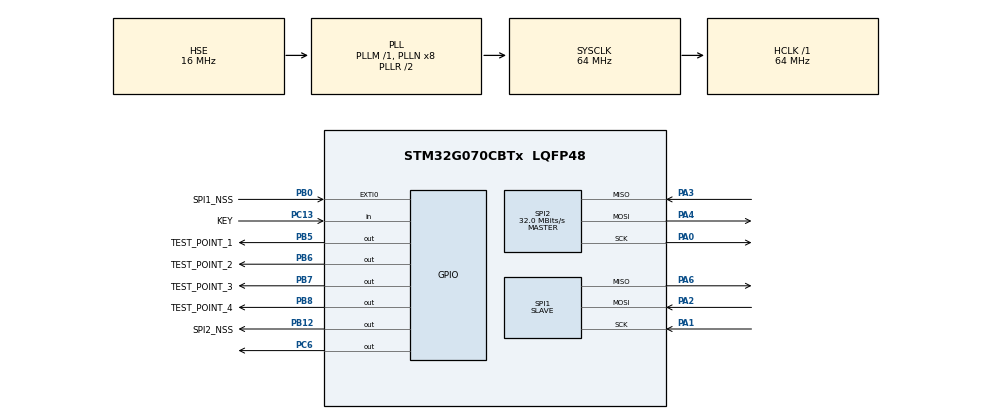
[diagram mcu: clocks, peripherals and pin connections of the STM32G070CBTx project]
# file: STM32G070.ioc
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Dma.Request0=SPI2_RX
Dma.Request1=SPI2_TX
Dma.Request2=SPI1_RX
Dma.Request3=SPI1_TX
Dma.SPI1_RX.2.Direction=DMA_PERIPH_TO_MEMORY
Dma.SPI1_RX.2.EventEnable=DISABLE
Dma.SPI1_RX.2.Instance=DMA1_Channel3
Dma.SPI1_RX.2.MemDataAlignment=DMA_MDATAALIGN_HALFWORD
Dma.SPI1_RX.2.MemInc=DMA_MINC_ENABLE
Dma.SPI1_RX.2.Mode=DMA_NORMAL
Dma.SPI1_RX.2.PeriphDataAlignment=DMA_PDATAALIGN_HALFWORD
Dma.SPI1_RX.2.PeriphInc=DMA_PINC_DISABLE
Dma.SPI1_RX.2.Polarity=HAL_DMAMUX_REQ_GEN_RISING
Dma.SPI1_RX.2.Priority=DMA_PRIORITY_VERY_HIGH
Dma.SPI1_RX.2.RequestNumber=1
Dma.SPI1_RX.2.SignalID=NONE
Dma.SPI1_RX.2.SyncEnable=DISABLE
Dma.SPI1_RX.2.SyncPolarity=HAL_DMAMUX_SYNC_NO_EVENT
Dma.SPI1_RX.2.SyncRequestNumber=1
Dma.SPI1_RX.2.SyncSignalID=NONE
Dma.SPI1_TX.3.Direction=DMA_MEMORY_TO_PERIPH
Dma.SPI1_TX.3.EventEnable=DISABLE
Dma.SPI1_TX.3.Instance=DMA1_Channel4
Dma.SPI1_TX.3.MemDataAlignment=DMA_MDATAALIGN_HALFWORD
Dma.SPI1_TX.3.MemInc=DMA_MINC_ENABLE
Dma.SPI1_TX.3.Mode=DMA_NORMAL
Dma.SPI1_TX.3.PeriphDataAlignment=DMA_PDATAALIGN_HALFWORD
Dma.SPI1_TX.3.PeriphInc=DMA_PINC_DISABLE
Dma.SPI1_TX.3.Polarity=HAL_DMAMUX_REQ_GEN_RISING
Dma.SPI1_TX.3.Priority=DMA_PRIORITY_LOW
Dma.SPI1_TX.3.RequestNumber=1
Dma.SPI1_TX.3.SignalID=NONE
Dma.SPI1_TX.3.SyncEnable=DISABLE
Dma.SPI1_TX.3.SyncPolarity=HAL_DMAMUX_SYNC_NO_EVENT
Dma.SPI1_TX.3.SyncRequestNumber=1
Dma.SPI1_TX.3.SyncSignalID=NONE
Dma.SPI2_RX.0.Direction=DMA_PERIPH_TO_MEMORY
Dma.SPI2_RX.0.EventEnable=DISABLE
Dma.SPI2_RX.0.Instance=DMA1_Channel1
Dma.SPI2_RX.0.MemDataAlignment=DMA_MDATAALIGN_HALFWORD
Dma.SPI2_RX.0.MemInc=DMA_MINC_ENABLE
Dma.SPI2_RX.0.Mode=DMA_NORMAL
Dma.SPI2_RX.0.PeriphDataAlignment=DMA_PDATAALIGN_HALFWORD
Dma.SPI2_RX.0.PeriphInc=DMA_PINC_DISABLE
Dma.SPI2_RX.0.Polarity=HAL_DMAMUX_REQ_GEN_RISING
Dma.SPI2_RX.0.Priority=DMA_PRIORITY_HIGH
Dma.SPI2_RX.0.RequestNumber=1
Dma.SPI2_RX.0.SignalID=NONE
Dma.SPI2_RX.0.SyncEnable=ENABLE
Dma.SPI2_RX.0.SyncPolarity=HAL_DMAMUX_SYNC_RISING
Dma.SPI2_RX.0.SyncRequestNumber=1
Dma.SPI2_RX.0.SyncSignalID=NONE
Dma.SPI2_TX.1.Direction=DMA_MEMORY_TO_PERIPH
Dma.SPI2_TX.1.EventEnable=DISABLE
Dma.SPI2_TX.1.Instance=DMA1_Channel2
Dma.SPI2_TX.1.MemDataAlignment=DMA_MDATAALIGN_HALFWORD
Dma.SPI2_TX.1.MemInc=DMA_MINC_ENABLE
Dma.SPI2_TX.1.Mode=DMA_NORMAL
Dma.SPI2_TX.1.PeriphDataAlignment=DMA_PDATAALIGN_HALFWORD
Dma.SPI2_TX.1.PeriphInc=DMA_PINC_DISABLE
Dma.SPI2_TX.1.Polarity=HAL_DMAMUX_REQ_GEN_RISING
Dma.SPI2_TX.1.Priority=DMA_PRIORITY_LOW
Dma.SPI2_TX.1.RequestNumber=1
Dma.SPI2_TX.1.SignalID=NONE
Dma.SPI2_TX.1.SyncEnable=DISABLE
Dma.SPI2_TX.1.SyncPolarity=HAL_DMAMUX_SYNC_NO_EVENT
Dma.SPI2_TX.1.SyncRequestNumber=1
Dma.SPI2_TX.1.SyncSignalID=NONE
Mcu.Family=STM32G0
Mcu.Name=STM32G070CBTx
Mcu.Package=LQFP48
NVIC.DMA1_Ch4_7_DMAMUX1_OVR_IRQn=true\:0\:0\:false\:false\:true\:false\:true\:true
NVIC.DMA1_Channel1_IRQn=true\:0\:0\:false\:false\:true\:false\:true\:true
NVIC.DMA1_Channel2_3_IRQn=true\:0\:0\:false\:false\:true\:false\:true\:true
NVIC.EXTI0_1_IRQn=true\:0\:0\:false\:false\:true\:true\:true\:true
NVIC.SPI1_IRQn=true\:0\:0\:false\:false\:true\:true\:true\:true
NVIC.SPI2_IRQn=true\:0\:0\:false\:false\:true\:true\:true\:true
PA0.GPIO_Speed=GPIO_SPEED_FREQ_VERY_HIGH
PA0.Mode=Full_Duplex_Master
PA0.Signal=SPI2_SCK
PA1.GPIO_Speed=GPIO_SPEED_FREQ_VERY_HIGH
PA1.Mode=Full_Duplex_Slave
PA1.Signal=SPI1_SCK
PA13.Mode=Serial_Wire
PA13.Signal=SYS_SWDIO
PA14-BOOT0.Mode=Serial_Wire
PA14-BOOT0.Signal=SYS_SWCLK
PA2.GPIO_Speed=GPIO_SPEED_FREQ_VERY_HIGH
PA2.Mode=Full_Duplex_Slave
PA2.Signal=SPI1_MOSI
PA3.GPIO_Speed=GPIO_SPEED_FREQ_VERY_HIGH
PA3.Mode=Full_Duplex_Master
PA3.Signal=SPI2_MISO
PA4.GPIO_Speed=GPIO_SPEED_FREQ_VERY_HIGH
PA4.Mode=Full_Duplex_Master
PA4.Signal=SPI2_MOSI
PA6.GPIO_Speed=GPIO_SPEED_FREQ_VERY_HIGH
PA6.Mode=Full_Duplex_Slave
PA6.Signal=SPI1_MISO
PB0.GPIO_Label=SPI1_NSS
PB0.GPIO_ModeDefaultEXTI=GPIO_MODE_IT_RISING_FALLING
PB0.Signal=GPXTI0
PB12.GPIO_Label=SPI2_NSS
PB12.GPIO_Speed=GPIO_SPEED_FREQ_VERY_HIGH
PB12.PinState=GPIO_PIN_SET
PB12.Signal=GPIO_Output
PB5.GPIO_Label=TEST_POINT_1
PB5.GPIO_Speed=GPIO_SPEED_FREQ_VERY_HIGH
PB5.Signal=GPIO_Output
PB6.GPIO_FM6=SYSCFG_FASTMODEPLUS_PB6
PB6.GPIO_Label=TEST_POINT_2
PB6.GPIO_Speed=GPIO_SPEED_FREQ_VERY_HIGH
PB6.Signal=GPIO_Output
PB7.GPIO_FM7=SYSCFG_FASTMODEPLUS_PB7
PB7.GPIO_Label=TEST_POINT_3
PB7.GPIO_Speed=GPIO_SPEED_FREQ_VERY_HIGH
PB7.Signal=GPIO_Output
PB8.GPIO_FM8=SYSCFG_FASTMODEPLUS_PB8
PB8.GPIO_Label=TEST_POINT_4
PB8.GPIO_Speed=GPIO_SPEED_FREQ_VERY_HIGH
PB8.Signal=GPIO_Output
PC13.GPIO_Label=KEY
PC13.GPIO_PuPd=GPIO_PULLUP
PC13.Signal=GPIO_Input
PC6.GPIO_Speed=GPIO_SPEED_FREQ_VERY_HIGH
PC6.Signal=GPIO_Output
PF0-OSC_IN\ (PF0).Mode=HSE-External-Oscillator
PF0-OSC_IN\ (PF0).Signal=RCC_OSC_IN
PF1-OSC_OUT\ (PF1).Mode=HSE-External-Oscillator
PF1-OSC_OUT\ (PF1).Signal=RCC_OSC_OUT
ProjectManager.HeapSize=0x200
ProjectManager.StackSize=0x400
ProjectManager.TargetToolchain=EWARM V8.50
RCC.ADCFreq_Value=64000000
RCC.AHBFreq_Value=64000000
RCC.CortexFreq_Value=64000000
RCC.EXTERNAL_CLOCK_VALUE=48000
RCC.HCLKFreq_Value=64000000
RCC.HSE_VALUE=16000000
RCC.HSI_VALUE=16000000
RCC.LSE_VALUE=32768
RCC.PLLSourceVirtual=RCC_PLLSOURCE_HSE
RCC.RCC_MCODiv=RCC_MCODIV_2
RCC.SYSCLKFreq_VALUE=64000000
RCC.SYSCLKSource=RCC_SYSCLKSOURCE_PLLCLK
RCC.VCOOutputFreq_Value=128000000
SPI1.DataSize=SPI_DATASIZE_16BIT
SPI1.Direction=SPI_DIRECTION_2LINES
SPI1.Mode=SPI_MODE_SLAVE
SPI1.VirtualType=VM_SLAVE
SPI2.BaudRatePrescaler=SPI_BAUDRATEPRESCALER_2
SPI2.CalculateBaudRate=32.0 MBits/s
SPI2.DataSize=SPI_DATASIZE_16BIT
SPI2.Direction=SPI_DIRECTION_2LINES
SPI2.Mode=SPI_MODE_MASTER
SPI2.VirtualType=VM_MASTER
board=custom

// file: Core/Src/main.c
/* USER CODE BEGIN Header */
/**
  ******************************************************************************
  * @file           : main.c
  * @brief          : Main program body
  ******************************************************************************
  * @attention
  *
  * Copyright (c) 2022 STMicroelectronics.
  * All rights reserved.
  *
  * This software is licensed under terms that can be found in the LICENSE file
  * in the root directory of this software component.
  * If no LICENSE file comes with this software, it is provided AS-IS.
  *
  ******************************************************************************
  */
/* USER CODE END Header */
#include "main.h"

/* USER CODE BEGIN Includes */
#include "stm32g070xx.h"
/* USER CODE END Includes */

/* USER CODE BEGIN PD */
#define MASTER_TX_RX_BUF_LEN    1024
#define SLAVE_TX_RX_BUF_LEN     MASTER_TX_RX_BUF_LEN

/*#define SPI2_NSS_H2L()          HAL_GPIO_WritePin(SPI2_NSS_GPIO_Port, SPI2_NSS_Pin, GPIO_PIN_RESET)
#define SPI2_NSS_L2H()          HAL_GPIO_WritePin(SPI2_NSS_GPIO_Port, SPI2_NSS_Pin, GPIO_PIN_SET)*/
#define SPI2_NSS_H2L()          SPI2_NSS_GPIO_Port->BRR = (uint32_t)SPI2_NSS_Pin
#define SPI2_NSS_L2H()          SPI2_NSS_GPIO_Port->BSRR = (uint32_t)SPI2_NSS_Pin
/* USER CODE END PD */

SPI_HandleTypeDef hspi1;
SPI_HandleTypeDef hspi2;
DMA_HandleTypeDef hdma_spi1_rx;
DMA_HandleTypeDef hdma_spi1_tx;
DMA_HandleTypeDef hdma_spi2_rx;
DMA_HandleTypeDef hdma_spi2_tx;

/* USER CODE BEGIN PV */
uint16_t        masterTxBuf[MASTER_TX_RX_BUF_LEN];
uint16_t        masterRxBuf[MASTER_TX_RX_BUF_LEN];
uint16_t        slaveTxBuf[SLAVE_TX_RX_BUF_LEN];
uint16_t        slaveRxBuf[SLAVE_TX_RX_BUF_LEN];
uint32_t        time;
/* USER CODE END PV */

void SystemClock_Config(void);
static void MX_GPIO_Init(void);
static void MX_DMA_Init(void);
static void MX_SPI1_Init(void);
static void MX_SPI2_Init(void);
/* USER CODE BEGIN PFP */
void protocol(uint16_t *buf, uint32_t len);
/* USER CODE END PFP */

/* USER CODE BEGIN 0 */

/**
  * @brief  exchange protocol implementation
  * @param[in]  data buffer
  * @param[in]  data length
  * @retval None
  */
void protocol(uint16_t *buf, uint32_t len)
{
        // we get here only if we get a full-size buffer
}

/**
  * @brief  Tx and Rx Transfer completed callback.
  * @param  hspi pointer to a SPI_HandleTypeDef structure that contains the configuration information for SPI module.
  * @retval None
  */
void HAL_SPI_TxRxCpltCallback(SPI_HandleTypeDef *hspi)
{
        if(hspi->Instance == SPI1)
        {
                protocol(slaveRxBuf, SLAVE_TX_RX_BUF_LEN);
        }
}

/**
  * @brief  EXTI line detection callback.
  * @param  GPIO_Pin Specifies the port pin connected to corresponding EXTI line.
  * @retval None
  */
void HAL_GPIO_EXTI_Falling_Callback(uint16_t GPIO_Pin)
{
        HAL_SPI_TransmitReceive_DMA(&hspi1, (uint8_t *)&slaveTxBuf, (uint8_t *)&slaveRxBuf, SLAVE_TX_RX_BUF_LEN);
        GPIOC->BRR =  0xffffffff; // устанавливаем 0 на всем порте
}

/**
  * @brief  EXTI line detection callback.
  * @param  GPIO_Pin Specifies the port pin connected to corresponding EXTI line.
  * @retval None
  */
void HAL_GPIO_EXTI_Rising_Callback(uint16_t GPIO_Pin)
{
        if(hdma_spi1_rx.Instance->CNDTR)
        {
                uint32_t Len = SLAVE_TX_RX_BUF_LEN - hdma_spi1_rx.Instance->CNDTR; // количество полученых слов
                HAL_SPI_DMAStop(&hspi1);
        }
}
/* USER CODE END 0 */

int main(void)
{

  /* MCU Configuration--------------------------------------------------------*/

  /* Reset of all peripherals, Initializes the Flash interface and the Systick. */
  HAL_Init();

  /* Configure the system clock */
  SystemClock_Config();

  /* Initialize all configured peripherals */
  MX_GPIO_Init();
  MX_DMA_Init();
  MX_SPI1_Init();
  MX_SPI2_Init();
  /* USER CODE BEGIN 2 */
        for(uint16_t i = 0;  i < MASTER_TX_RX_BUF_LEN; i++) // generate a set of data for easy tracking of changes in debug mode
                masterTxBuf[i] = MASTER_TX_RX_BUF_LEN - i - 1;
        for(uint16_t i = 0;  i < SLAVE_TX_RX_BUF_LEN; i++) // generate a set of data for easy tracking of changes in debug mode
                slaveTxBuf[i]  = SLAVE_TX_RX_BUF_LEN - i - 1;
  /* USER CODE END 2 */

  /* Infinite loop */
  /* USER CODE BEGIN WHILE */
  while(1)
  {
          time = HAL_GetTick();
          GPIOC->BSRR = 0xffffffff; // устанавливаем 1 на всем порте
          SPI2_NSS_H2L();
          //HAL_Delay(1);
          //HAL_SPI_TransmitReceive(&hspi2, (uint8_t *)&masterTxBuf, (uint8_t *)&masterRxBuf, MASTER_TX_BUF_LEN, 2000);
          HAL_SPI_TransmitReceive_DMA(&hspi2, (uint8_t *)&masterTxBuf, (uint8_t *)&masterRxBuf, MASTER_TX_RX_BUF_LEN);
          while(hdma_spi2_tx.Instance->CNDTR); // wait for the end of the data transfer
          SPI2_NSS_L2H();
          time = HAL_GetTick() - time;
          uint8_t c = 0;
    /* USER CODE END WHILE */

    /* USER CODE BEGIN 3 */
          //HAL_SPI_DMAStop(&hspi1);
  }
  /* USER CODE END 3 */
}

void SystemClock_Config(void)
{
  RCC_OscInitTypeDef RCC_OscInitStruct = {0};
  RCC_ClkInitTypeDef RCC_ClkInitStruct = {0};

  /** Configure the main internal regulator output voltage
  */
  HAL_PWREx_ControlVoltageScaling(PWR_REGULATOR_VOLTAGE_SCALE1);

  /** Initializes the RCC Oscillators according to the specified parameters
  * in the RCC_OscInitTypeDef structure.
  */
  RCC_OscInitStruct.OscillatorType = RCC_OSCILLATORTYPE_HSE;
  RCC_OscInitStruct.HSEState = RCC_HSE_ON;
  RCC_OscInitStruct.PLL.PLLState = RCC_PLL_ON;
  RCC_OscInitStruct.PLL.PLLSource = RCC_PLLSOURCE_HSE;
  RCC_OscInitStruct.PLL.PLLM = RCC_PLLM_DIV1;
  RCC_OscInitStruct.PLL.PLLN = 8;
  RCC_OscInitStruct.PLL.PLLP = RCC_PLLP_DIV2;
  RCC_OscInitStruct.PLL.PLLR = RCC_PLLR_DIV2;
  if (HAL_RCC_OscConfig(&RCC_OscInitStruct) != HAL_OK)
  {
    Error_Handler();
  }

  /** Initializes the CPU, AHB and APB buses clocks
  */
  RCC_ClkInitStruct.ClockType = RCC_CLOCKTYPE_HCLK|RCC_CLOCKTYPE_SYSCLK
                              |RCC_CLOCKTYPE_PCLK1;
  RCC_ClkInitStruct.SYSCLKSource = RCC_SYSCLKSOURCE_PLLCLK;
  RCC_ClkInitStruct.AHBCLKDivider = RCC_SYSCLK_DIV1;
  RCC_ClkInitStruct.APB1CLKDivider = RCC_HCLK_DIV1;

  if (HAL_RCC_ClockConfig(&RCC_ClkInitStruct, FLASH_LATENCY_2) != HAL_OK)
  {
    Error_Handler();
  }
  HAL_RCC_MCOConfig(RCC_MCO1, RCC_MCO1SOURCE_SYSCLK, RCC_MCODIV_2);
}

static void MX_SPI1_Init(void)
{

  /* SPI1 parameter configuration*/
  hspi1.Instance = SPI1;
  hspi1.Init.Mode = SPI_MODE_SLAVE;
  hspi1.Init.Direction = SPI_DIRECTION_2LINES;
  hspi1.Init.DataSize = SPI_DATASIZE_16BIT;
  hspi1.Init.CLKPolarity = SPI_POLARITY_LOW;
  hspi1.Init.CLKPhase = SPI_PHASE_1EDGE;
  hspi1.Init.NSS = SPI_NSS_SOFT;
  hspi1.Init.FirstBit = SPI_FIRSTBIT_MSB;
  hspi1.Init.TIMode = SPI_TIMODE_DISABLE;
  hspi1.Init.CRCCalculation = SPI_CRCCALCULATION_DISABLE;
  hspi1.Init.CRCPolynomial = 7;
  hspi1.Init.CRCLength = SPI_CRC_LENGTH_DATASIZE;
  hspi1.Init.NSSPMode = SPI_NSS_PULSE_DISABLE;
  if (HAL_SPI_Init(&hspi1) != HAL_OK)
  {
    Error_Handler();
  }

}

static void MX_SPI2_Init(void)
{

  /* SPI2 parameter configuration*/
  hspi2.Instance = SPI2;
  hspi2.Init.Mode = SPI_MODE_MASTER;
  hspi2.Init.Direction = SPI_DIRECTION_2LINES;
  hspi2.Init.DataSize = SPI_DATASIZE_16BIT;
  hspi2.Init.CLKPolarity = SPI_POLARITY_LOW;
  hspi2.Init.CLKPhase = SPI_PHASE_1EDGE;
  hspi2.Init.NSS = SPI_NSS_SOFT;
  hspi2.Init.BaudRatePrescaler = SPI_BAUDRATEPRESCALER_2;
  hspi2.Init.FirstBit = SPI_FIRSTBIT_MSB;
  hspi2.Init.TIMode = SPI_TIMODE_DISABLE;
  hspi2.Init.CRCCalculation = SPI_CRCCALCULATION_DISABLE;
  hspi2.Init.CRCPolynomial = 7;
  hspi2.Init.CRCLength = SPI_CRC_LENGTH_DATASIZE;
  hspi2.Init.NSSPMode = SPI_NSS_PULSE_ENABLE;
  if (HAL_SPI_Init(&hspi2) != HAL_OK)
  {
    Error_Handler();
  }

}

static void MX_DMA_Init(void)
{

  /* DMA controller clock enable */
  __HAL_RCC_DMA1_CLK_ENABLE();

  /* DMA interrupt init */
  /* DMA1_Channel1_IRQn interrupt configuration */
  HAL_NVIC_SetPriority(DMA1_Channel1_IRQn, 0, 0);
  HAL_NVIC_EnableIRQ(DMA1_Channel1_IRQn);
  /* DMA1_Channel2_3_IRQn interrupt configuration */
  HAL_NVIC_SetPriority(DMA1_Channel2_3_IRQn, 0, 0);
  HAL_NVIC_EnableIRQ(DMA1_Channel2_3_IRQn);
  /* DMA1_Ch4_7_DMAMUX1_OVR_IRQn interrupt configuration */
  HAL_NVIC_SetPriority(DMA1_Ch4_7_DMAMUX1_OVR_IRQn, 0, 0);
  HAL_NVIC_EnableIRQ(DMA1_Ch4_7_DMAMUX1_OVR_IRQn);

}

static void MX_GPIO_Init(void)
{
  GPIO_InitTypeDef GPIO_InitStruct = {0};

  /* GPIO Ports Clock Enable */
  __HAL_RCC_GPIOC_CLK_ENABLE();
  __HAL_RCC_GPIOF_CLK_ENABLE();
  __HAL_RCC_GPIOA_CLK_ENABLE();
  __HAL_RCC_GPIOB_CLK_ENABLE();

  /*Configure GPIO pin Output Level */
  HAL_GPIO_WritePin(SPI2_NSS_GPIO_Port, SPI2_NSS_Pin, GPIO_PIN_SET);

  /*Configure GPIO pin Output Level */
  HAL_GPIO_WritePin(GPIOC, GPIO_PIN_6, GPIO_PIN_RESET);

  /*Configure GPIO pin Output Level */
  HAL_GPIO_WritePin(GPIOB, TEST_POINT_1_Pin|TEST_POINT_2_Pin|TEST_POINT_3_Pin|TEST_POINT_4_Pin, GPIO_PIN_RESET);

  /*Configure GPIO pin : KEY_Pin */
  GPIO_InitStruct.Pin = KEY_Pin;
  GPIO_InitStruct.Mode = GPIO_MODE_INPUT;
  GPIO_InitStruct.Pull = GPIO_PULLUP;
  HAL_GPIO_Init(KEY_GPIO_Port, &GPIO_InitStruct);

  /*Configure GPIO pin : SPI1_NSS_Pin */
  GPIO_InitStruct.Pin = SPI1_NSS_Pin;
  GPIO_InitStruct.Mode = GPIO_MODE_IT_RISING_FALLING;
  GPIO_InitStruct.Pull = GPIO_NOPULL;
  HAL_GPIO_Init(SPI1_NSS_GPIO_Port, &GPIO_InitStruct);

  /*Configure GPIO pins : SPI2_NSS_Pin TEST_POINT_1_Pin TEST_POINT_2_Pin TEST_POINT_3_Pin
                           TEST_POINT_4_Pin */
  GPIO_InitStruct.Pin = SPI2_NSS_Pin|TEST_POINT_1_Pin|TEST_POINT_2_Pin|TEST_POINT_3_Pin
                          |TEST_POINT_4_Pin;
  GPIO_InitStruct.Mode = GPIO_MODE_OUTPUT_PP;
  GPIO_InitStruct.Pull = GPIO_NOPULL;
  GPIO_InitStruct.Speed = GPIO_SPEED_FREQ_VERY_HIGH;
  HAL_GPIO_Init(GPIOB, &GPIO_InitStruct);

  /*Configure GPIO pin : PA8 */
  GPIO_InitStruct.Pin = GPIO_PIN_8;
  GPIO_InitStruct.Mode = GPIO_MODE_AF_PP;
  GPIO_InitStruct.Pull = GPIO_NOPULL;
  GPIO_InitStruct.Speed = GPIO_SPEED_FREQ_LOW;
  GPIO_InitStruct.Alternate = GPIO_AF0_MCO;
  HAL_GPIO_Init(GPIOA, &GPIO_InitStruct);

  /*Configure GPIO pin : PC6 */
  GPIO_InitStruct.Pin = GPIO_PIN_6;
  GPIO_InitStruct.Mode = GPIO_MODE_OUTPUT_PP;
  GPIO_InitStruct.Pull = GPIO_NOPULL;
  GPIO_InitStruct.Speed = GPIO_SPEED_FREQ_VERY_HIGH;
  HAL_GPIO_Init(GPIOC, &GPIO_InitStruct);

  /**/
  __HAL_SYSCFG_FASTMODEPLUS_ENABLE(SYSCFG_FASTMODEPLUS_PB6);

  /**/
  __HAL_SYSCFG_FASTMODEPLUS_ENABLE(SYSCFG_FASTMODEPLUS_PB7);

  /**/
  __HAL_SYSCFG_FASTMODEPLUS_ENABLE(SYSCFG_FASTMODEPLUS_PB8);

  /* EXTI interrupt init*/
  HAL_NVIC_SetPriority(EXTI0_1_IRQn, 0, 0);
  HAL_NVIC_EnableIRQ(EXTI0_1_IRQn);

}

void Error_Handler(void)
{
  __disable_irq();
  while (1)
  {
  }
}
